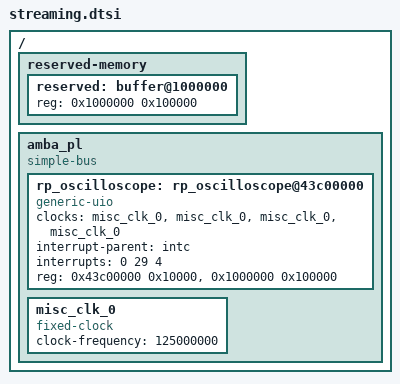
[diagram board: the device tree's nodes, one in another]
/ {
  reserved-memory {
    #address-cells = <1>;
    #size-cells = <1>; 
    ranges;
  
    reserved: buffer@1000000 {
     reg = <0x1000000 0x100000>;
   };
  };

  amba_pl: amba_pl {
                #address-cells = <1>;
                #size-cells = <1>;
                compatible = "simple-bus";
                ranges ;
                rp_oscilloscope: rp_oscilloscope@43c00000 {
                        clock-names = "clk", "s_axi_reg_aclk", "m_axi_osc1_aclk", "m_axi_osc2_aclk";
                        clocks = <&misc_clk_0>, <&misc_clk_0>, <&misc_clk_0>, <&misc_clk_0>;
                        compatible = "xlnx";
                        interrupt-names = "intr";
                        interrupt-parent = <&intc>;
                        interrupts = <0 29 4>;
                        reg = <0x43c00000 0x10000>;
                };
                misc_clk_0: misc_clk_0 {
                        #clock-cells = <0>;
                        clock-frequency = <125000000>;
                        compatible = "fixed-clock";
                };

        };
};

&rp_oscilloscope {
 compatible = "generic-uio";
 reg = <0x43c00000 0x10000>, <0x1000000 0x100000>;
 reg-names = "regset", "buffer";
};
